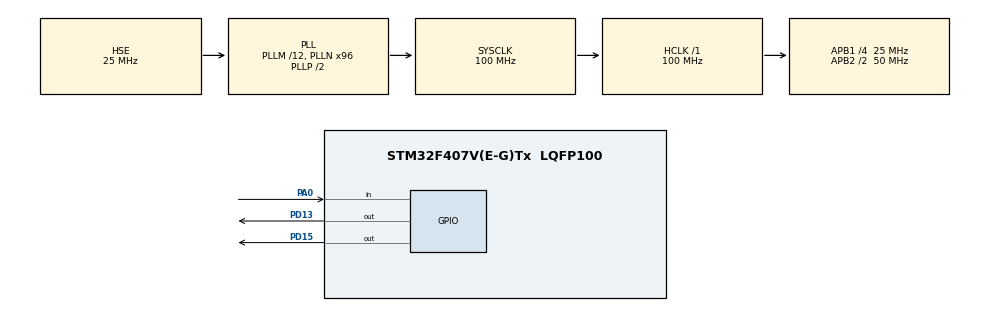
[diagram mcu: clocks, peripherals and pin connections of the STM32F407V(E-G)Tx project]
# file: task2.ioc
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FREERTOS.Tasks01=defaultTask,24,128,StartDefaultTask,Default,NULL,Dynamic,NULL,NULL;ClignoteTask,9,128,ClignoteTask_Cbk,Default,NULL,Dynamic,NULL,NULL;ButtonTask,12,128,ButtonTask_Cbk,Default,NULL,Dynamic,NULL,NULL
Mcu.Family=STM32F4
Mcu.Name=STM32F407V(E-G)Tx
Mcu.Package=LQFP100
NVIC.PriorityGroup=NVIC_PRIORITYGROUP_4
NVIC.TIM6_DAC_IRQn=true\:15\:0\:false\:false\:true\:false\:false\:true\:true
NVIC.TimeBase=TIM6_DAC_IRQn
NVIC.TimeBaseIP=TIM6
PA0-WKUP.Signal=GPIO_Input
PD13.Signal=GPIO_Output
PD15.Signal=GPIO_Output
PH0-OSC_IN.Mode=HSE-External-Oscillator
PH0-OSC_IN.Signal=RCC_OSC_IN
PH1-OSC_OUT.Mode=HSE-External-Oscillator
PH1-OSC_OUT.Signal=RCC_OSC_OUT
ProjectManager.HeapSize=0x200
ProjectManager.StackSize=0x400
ProjectManager.TargetToolchain=Makefile
RCC.48MHZClocksFreq_Value=50000000
RCC.AHBFreq_Value=100000000
RCC.APB1CLKDivider=RCC_HCLK_DIV4
RCC.APB1Freq_Value=25000000
RCC.APB1TimFreq_Value=50000000
RCC.APB2CLKDivider=RCC_HCLK_DIV2
RCC.APB2Freq_Value=50000000
RCC.APB2TimFreq_Value=100000000
RCC.CortexFreq_Value=100000000
RCC.HCLKFreq_Value=100000000
RCC.HSE_VALUE=25000000
RCC.HSI_VALUE=16000000
RCC.LSE_VALUE=32768
RCC.PLLM=12
RCC.PLLN=96
RCC.PLLSourceVirtual=RCC_PLLSOURCE_HSE
RCC.SYSCLKFreq_VALUE=100000000
RCC.SYSCLKSource=RCC_SYSCLKSOURCE_PLLCLK
RCC.VCOOutputFreq_Value=200000000
VP_FREERTOS_VS_CMSIS_V2.Mode=CMSIS_V2
VP_SYS_VS_tim6.Mode=TIM6
board=custom

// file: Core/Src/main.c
/* USER CODE BEGIN Header */
/**
  ******************************************************************************
  * @file           : main.c
  * @brief          : Main program body
  ******************************************************************************
  * @attention
  *
  * Copyright (c) 2025 STMicroelectronics.
  * All rights reserved.
  *
  * This software is licensed under terms that can be found in the LICENSE file
  * in the root directory of this software component.
  * If no LICENSE file comes with this software, it is provided AS-IS.
  *
  ******************************************************************************
  */
/* USER CODE END Header */
#include "main.h"
#include "cmsis_os.h"
#include "gpio.h"

void SystemClock_Config(void);
void MX_FREERTOS_Init(void);

int main(void){

  /* MCU Configuration--------------------------------------------------------*/

  /* Reset of all peripherals, Initializes the Flash interface and the Systick. */
  HAL_Init();

  /* Configure the system clock */
  SystemClock_Config();

  /* Initialize all configured peripherals */
  MX_GPIO_Init();

  /* Init scheduler */
  osKernelInitialize();

  /* Call init function for freertos objects (in cmsis_os2.c) */
  MX_FREERTOS_Init();

  /* Start scheduler */
  osKernelStart();

  /* We should never get here as control is now taken by the scheduler */

  /* Infinite loop */
  while (1)
  {

  }
}

void SystemClock_Config(void)
{
  RCC_OscInitTypeDef RCC_OscInitStruct = {0};
  RCC_ClkInitTypeDef RCC_ClkInitStruct = {0};

  /** Configure the main internal regulator output voltage
  */
  __HAL_RCC_PWR_CLK_ENABLE();
  __HAL_PWR_VOLTAGESCALING_CONFIG(PWR_REGULATOR_VOLTAGE_SCALE1);

  /** Initializes the RCC Oscillators according to the specified parameters
  * in the RCC_OscInitTypeDef structure.
  */
  RCC_OscInitStruct.OscillatorType = RCC_OSCILLATORTYPE_HSE;
  RCC_OscInitStruct.HSEState = RCC_HSE_ON;
  RCC_OscInitStruct.PLL.PLLState = RCC_PLL_ON;
  RCC_OscInitStruct.PLL.PLLSource = RCC_PLLSOURCE_HSE;
  RCC_OscInitStruct.PLL.PLLM = 12;
  RCC_OscInitStruct.PLL.PLLN = 96;
  RCC_OscInitStruct.PLL.PLLP = RCC_PLLP_DIV2;
  RCC_OscInitStruct.PLL.PLLQ = 4;
  if (HAL_RCC_OscConfig(&RCC_OscInitStruct) != HAL_OK)
  {
    Error_Handler();
  }

  /** Initializes the CPU, AHB and APB buses clocks
  */
  RCC_ClkInitStruct.ClockType = RCC_CLOCKTYPE_HCLK|RCC_CLOCKTYPE_SYSCLK
                              |RCC_CLOCKTYPE_PCLK1|RCC_CLOCKTYPE_PCLK2;
  RCC_ClkInitStruct.SYSCLKSource = RCC_SYSCLKSOURCE_PLLCLK;
  RCC_ClkInitStruct.AHBCLKDivider = RCC_SYSCLK_DIV1;
  RCC_ClkInitStruct.APB1CLKDivider = RCC_HCLK_DIV4;
  RCC_ClkInitStruct.APB2CLKDivider = RCC_HCLK_DIV2;

  if (HAL_RCC_ClockConfig(&RCC_ClkInitStruct, FLASH_LATENCY_3) != HAL_OK)
  {
    Error_Handler();
  }
}

void HAL_TIM_PeriodElapsedCallback(TIM_HandleTypeDef *htim)
{
  if (htim->Instance == TIM6)
  {
    HAL_IncTick();
  }
}

void Error_Handler(void)
{
  __disable_irq();
  while (1)
  {
  }
}

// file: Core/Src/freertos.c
/* USER CODE BEGIN Header */
/**
 ******************************************************************************
 * File Name          : freertos.c
 * Description        : Code for freertos applications
 ******************************************************************************
 * @attention
 *
 * Copyright (c) 2025 STMicroelectronics.
 * All rights reserved.
 *
 * This software is licensed under terms that can be found in the LICENSE file
 * in the root directory of this software component.
 * If no LICENSE file comes with this software, it is provided AS-IS.
 *
 ******************************************************************************
 */
/* USER CODE END Header */

#include "FreeRTOS.h"
#include "cmsis_os.h"
#include "main.h"
#include "task.h"

/* Definitions for defaultTask */
osThreadId_t defaultTaskHandle;
const osThreadAttr_t defaultTask_attributes = {
    .name = "defaultTask",
    .stack_size = 128 * 4,
    .priority = (osPriority_t)osPriorityNormal,
};
/* Definitions for ClignoteTask */
osThreadId_t ClignoteTaskHandle;
const osThreadAttr_t ClignoteTask_attributes = {
    .name = "ClignoteTask",
    .stack_size = 128 * 4,
    .priority = (osPriority_t)osPriorityLow1,
};
/* Definitions for ButtonTask */
osThreadId_t ButtonTaskHandle;
const osThreadAttr_t ButtonTask_attributes = {
    .name = "ButtonTask",
    .stack_size = 128 * 4,
    .priority = (osPriority_t)osPriorityLow4,
};

void StartDefaultTask(void* argument);
void ClignoteTask_Cbk(void* argument);
void ButtonTask_Cbk(void* argument);

void MX_FREERTOS_Init(void); /* (MISRA C 2004 rule 8.1) */

void MX_FREERTOS_Init(void)
{

    /* Create the thread(s) */
    /* creation of defaultTask */
    defaultTaskHandle =
        osThreadNew(StartDefaultTask, NULL, &defaultTask_attributes);

    /* creation of ClignoteTask */
    ClignoteTaskHandle =
        osThreadNew(ClignoteTask_Cbk, NULL, &ClignoteTask_attributes);

    /* creation of ButtonTask */
    ButtonTaskHandle =
        osThreadNew(ButtonTask_Cbk, NULL, &ButtonTask_attributes);

}

void StartDefaultTask(void* argument)
{
    for (;;)
    {
        osDelay(1);
    }
}

/* USER CODE BEGIN Header_ClignoteTask_Cbk */
/**
 * @brief Function implementing the ClignoteTask thread.
 * @param argument: Not used
 * @retval None
 */
volatile int btn_taskPeriod = 0 ;
volatile uint8_t LedTaskState = 0 ;
static TickType_t xLastWakeTime = 0;  // Make it static or global (NOT local)
volatile int i = 0 ;
volatile sum = 0 ;
volatile  TickType_t xStartTime = 0 ;
/* USER CODE END Header_ClignoteTask_Cbk */
void ClignoteTask_Cbk(void* argument)
{
    /* USER CODE BEGIN ClignoteTask_Cbk */
    /* Infinite loop */

    for (;;)
    {

        if (LedTaskState == 1 ){
            GPIO_PinState tmp = HAL_GPIO_ReadPin(GPIOD,GPIO_PIN_15);
            HAL_GPIO_WritePin(GPIOD,GPIO_PIN_15,tmp);
            LedTaskState = 0 ;

        }else {
            HAL_GPIO_TogglePin(GPIOD, GPIO_PIN_15);

        }

        xStartTime = xTaskGetTickCount();
        while (xTaskGetTickCount() - xStartTime <= (1000))
        {
        xLastWakeTime = xTaskGetTickCount();
        }

        xStartTime = 0 ;
    }
    /* USER CODE END ClignoteTask_Cbk */
}

/* USER CODE BEGIN Header_ButtonTask_Cbk */
uint8_t BtnState = 0;
/**
 * @brief Function implementing the ButtonTask thread.
 * @param argument: Not used
 * @retval None
 */
/* USER CODE END Header_ButtonTask_Cbk */
void ButtonTask_Cbk(void* argument)
{
    /* USER CODE BEGIN ButtonTask_Cbk */
    /* Infinite loop */

    for (;;)
    {

        int start = 0 ;
        BtnState = HAL_GPIO_ReadPin(GPIOA, GPIO_PIN_0);
        if (BtnState == 1)
        {
            osDelay(20);
            BtnState = HAL_GPIO_ReadPin(GPIOA, GPIO_PIN_0);
            if (BtnState == 1)
            {
                osThreadSuspend(ClignoteTaskHandle);
                HAL_GPIO_WritePin(GPIOD, GPIO_PIN_13, GPIO_PIN_RESET);
                LedTaskState = 1 ;
                start =  xTaskGetTickCount();
            }
            else
            {
                // HAL_GPIO_WritePin(GPIOD, GPIO_PIN_13, GPIO_PIN_SET);
                // osThreadResume(ClignoteTaskHandle);
                // do nohing
            }
        }
        else
        {
            HAL_GPIO_WritePin(GPIOD, GPIO_PIN_13, GPIO_PIN_SET);
            osThreadResume(ClignoteTaskHandle);
        }

        osDelay(80);
        int last = xTaskGetTickCount();
        btn_taskPeriod += (last - start);
    }
    /* USER CODE END ButtonTask_Cbk */
}
